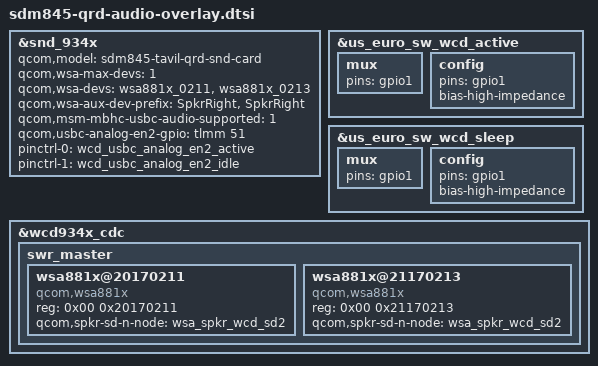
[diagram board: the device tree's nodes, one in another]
/*
 * Copyright (c) 2017-2018, The Linux Foundation. All rights reserved.
 *
 * This program is free software; you can redistribute it and/or modify
 * it under the terms of the GNU General Public License version 2 and
 * only version 2 as published by the Free Software Foundation.
 *
 * This program is distributed in the hope that it will be useful,
 * but WITHOUT ANY WARRANTY; without even the implied warranty of
 * MERCHANTABILITY or FITNESS FOR A PARTICULAR PURPOSE.  See the
 * GNU General Public License for more details.
 */

#include "sdm845-audio-overlay.dtsi"

&snd_934x {
	qcom,model = "sdm845-tavil-qrd-snd-card";

	qcom,wsa-max-devs = <1>;
	qcom,wsa-devs = <&wsa881x_0211>, <&wsa881x_0213>;
	qcom,wsa-aux-dev-prefix = "SpkrRight", "SpkrRight";

	qcom,msm-mbhc-usbc-audio-supported = <1>;

	qcom,usbc-analog-en2-gpio = <&tlmm 51 0>;
	pinctrl-names = "aud_active", "aud_sleep";
	pinctrl-0 = <&wcd_usbc_analog_en2_active>;
	pinctrl-1 = <&wcd_usbc_analog_en2_idle>;
};

&us_euro_sw_wcd_active {
	mux {
		pins = "gpio1";
	};

	config {
		pins = "gpio1";
		/delete-property/ output-high;
		bias-high-impedance;
	};
};

&us_euro_sw_wcd_sleep {
	mux {
		pins = "gpio1";
	};

	config {
		pins = "gpio1";
		/delete-property/ output-low;
		bias-high-impedance;
	};
};

&wcd934x_cdc {
	swr_master {
		wsa881x@20170211 {
			compatible = "qcom,wsa881x";
			reg = <0x00 0x20170211>;
			qcom,spkr-sd-n-node = <&wsa_spkr_wcd_sd2>;
		};

		wsa881x@21170213 {
			compatible = "qcom,wsa881x";
			reg = <0x00 0x21170213>;
			qcom,spkr-sd-n-node = <&wsa_spkr_wcd_sd2>;
		};
	};
};

